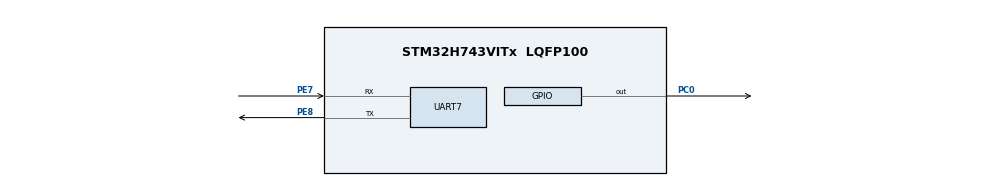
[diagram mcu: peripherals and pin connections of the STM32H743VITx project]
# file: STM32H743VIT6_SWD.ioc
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Mcu.Family=STM32H7
Mcu.Name=STM32H743VITx
Mcu.Package=LQFP100
NVIC.PriorityGroup=NVIC_PRIORITYGROUP_4
PA13\ (JTMS/SWDIO).Mode=JTAG_4_pins
PA13\ (JTMS/SWDIO).Signal=DEBUG_JTMS-SWDIO
PA14\ (JTCK/SWCLK).Mode=JTAG_4_pins
PA14\ (JTCK/SWCLK).Signal=DEBUG_JTCK-SWCLK
PA15\ (JTDI).Mode=JTAG_4_pins
PA15\ (JTDI).Signal=DEBUG_JTDI
PB3\ (JTDO/TRACESWO).Mode=JTAG_4_pins
PB3\ (JTDO/TRACESWO).Signal=DEBUG_JTDO-SWO
PC0.GPIO_ModeDefaultOutputPP=GPIO_MODE_OUTPUT_PP
PC0.GPIO_PuPd=GPIO_NOPULL
PC0.PinState=GPIO_PIN_SET
PC0.Signal=GPIO_Output
PE7.Mode=Asynchronous
PE7.Signal=UART7_RX
PE8.Mode=Asynchronous
PE8.Signal=UART7_TX
ProjectManager.HeapSize=0x200
ProjectManager.StackSize=0x400
ProjectManager.TargetToolchain=STM32CubeIDE
RCC.ADCFreq_Value=129000000
RCC.APB1Freq_Value=32000000
RCC.APB2Freq_Value=64000000
RCC.APB3Freq_Value=64000000
RCC.APB4Freq_Value=64000000
RCC.CortexFreq_Value=64000000
RCC.D2PPRE1=RCC_APB1_DIV2
RCC.HCLKFreq_Value=64000000
RCC.SYSCLKFreq_VALUE=64000000
RCC.USBFreq_Value=129000000
board=custom

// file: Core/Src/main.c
/* USER CODE BEGIN Header */
/**
  ******************************************************************************
  * @file           : main.c
  * @brief          : Main program body
  ******************************************************************************
  * @attention
  *
  * Copyright (c) 2022 STMicroelectronics.
  * All rights reserved.
  *
  * This software is licensed under terms that can be found in the LICENSE file
  * in the root directory of this software component.
  * If no LICENSE file comes with this software, it is provided AS-IS.
  *
  ******************************************************************************
  */
/* USER CODE END Header */
#include "main.h"

/* USER CODE BEGIN PM */
#define PRINT(...) printf(__VA_ARGS__)
/* USER CODE END PM */

UART_HandleTypeDef huart7;

void SystemClock_Config(void);
static void MX_GPIO_Init(void);
static void MX_UART7_Init(void);

/* USER CODE BEGIN 0 */
int __io_putchar(int ch)
{
	ITM_SendChar(ch);
	return(ch);
}
/* USER CODE END 0 */

int main(void)
{

  /* MCU Configuration--------------------------------------------------------*/

  /* Reset of all peripherals, Initializes the Flash interface and the Systick. */
  HAL_Init();

  /* Configure the system clock */
  SystemClock_Config();

  /* Initialize all configured peripherals */
  MX_GPIO_Init();
  MX_UART7_Init();
  /* USER CODE BEGIN 2 */
  PRINT("Led ON\n");
  HAL_Delay(1000);
  HAL_GPIO_TogglePin(GPIOC, GPIO_PIN_0);		// turn led (PC0) off
  PRINT("Led OFF\n");
  /* USER CODE END 2 */

  /* Infinite loop */
  while (1)
  {

  }
}

void SystemClock_Config(void)
{
  RCC_OscInitTypeDef RCC_OscInitStruct = {0};
  RCC_ClkInitTypeDef RCC_ClkInitStruct = {0};

  /** Supply configuration update enable
  */
  HAL_PWREx_ConfigSupply(PWR_LDO_SUPPLY);

  /** Configure the main internal regulator output voltage
  */
  __HAL_PWR_VOLTAGESCALING_CONFIG(PWR_REGULATOR_VOLTAGE_SCALE3);

  while(!__HAL_PWR_GET_FLAG(PWR_FLAG_VOSRDY)) {}

  /** Initializes the RCC Oscillators according to the specified parameters
  * in the RCC_OscInitTypeDef structure.
  */
  RCC_OscInitStruct.OscillatorType = RCC_OSCILLATORTYPE_HSI;
  RCC_OscInitStruct.HSIState = RCC_HSI_DIV1;
  RCC_OscInitStruct.HSICalibrationValue = RCC_HSICALIBRATION_DEFAULT;
  RCC_OscInitStruct.PLL.PLLState = RCC_PLL_NONE;
  if (HAL_RCC_OscConfig(&RCC_OscInitStruct) != HAL_OK)
  {
    Error_Handler();
  }

  /** Initializes the CPU, AHB and APB buses clocks
  */
  RCC_ClkInitStruct.ClockType = RCC_CLOCKTYPE_HCLK|RCC_CLOCKTYPE_SYSCLK
                              |RCC_CLOCKTYPE_PCLK1|RCC_CLOCKTYPE_PCLK2
                              |RCC_CLOCKTYPE_D3PCLK1|RCC_CLOCKTYPE_D1PCLK1;
  RCC_ClkInitStruct.SYSCLKSource = RCC_SYSCLKSOURCE_HSI;
  RCC_ClkInitStruct.SYSCLKDivider = RCC_SYSCLK_DIV1;
  RCC_ClkInitStruct.AHBCLKDivider = RCC_HCLK_DIV1;
  RCC_ClkInitStruct.APB3CLKDivider = RCC_APB3_DIV1;
  RCC_ClkInitStruct.APB1CLKDivider = RCC_APB1_DIV2;
  RCC_ClkInitStruct.APB2CLKDivider = RCC_APB2_DIV1;
  RCC_ClkInitStruct.APB4CLKDivider = RCC_APB4_DIV1;

  if (HAL_RCC_ClockConfig(&RCC_ClkInitStruct, FLASH_LATENCY_1) != HAL_OK)
  {
    Error_Handler();
  }
}

static void MX_UART7_Init(void)
{

  huart7.Instance = UART7;
  huart7.Init.BaudRate = 115200;
  huart7.Init.WordLength = UART_WORDLENGTH_8B;
  huart7.Init.StopBits = UART_STOPBITS_1;
  huart7.Init.Parity = UART_PARITY_NONE;
  huart7.Init.Mode = UART_MODE_TX_RX;
  huart7.Init.HwFlowCtl = UART_HWCONTROL_NONE;
  huart7.Init.OverSampling = UART_OVERSAMPLING_16;
  huart7.Init.OneBitSampling = UART_ONE_BIT_SAMPLE_DISABLE;
  huart7.Init.ClockPrescaler = UART_PRESCALER_DIV1;
  huart7.AdvancedInit.AdvFeatureInit = UART_ADVFEATURE_NO_INIT;
  if (HAL_UART_Init(&huart7) != HAL_OK)
  {
    Error_Handler();
  }
  if (HAL_UARTEx_SetTxFifoThreshold(&huart7, UART_TXFIFO_THRESHOLD_1_8) != HAL_OK)
  {
    Error_Handler();
  }
  if (HAL_UARTEx_SetRxFifoThreshold(&huart7, UART_RXFIFO_THRESHOLD_1_8) != HAL_OK)
  {
    Error_Handler();
  }
  if (HAL_UARTEx_DisableFifoMode(&huart7) != HAL_OK)
  {
    Error_Handler();
  }

}

static void MX_GPIO_Init(void)
{
  GPIO_InitTypeDef GPIO_InitStruct = {0};

  /* GPIO Ports Clock Enable */
  __HAL_RCC_GPIOC_CLK_ENABLE();
  __HAL_RCC_GPIOE_CLK_ENABLE();
  __HAL_RCC_GPIOA_CLK_ENABLE();
  __HAL_RCC_GPIOB_CLK_ENABLE();

  /*Configure GPIO pin Output Level */
  HAL_GPIO_WritePin(GPIOC, GPIO_PIN_0, GPIO_PIN_SET);

  /*Configure GPIO pin : PC0 */
  GPIO_InitStruct.Pin = GPIO_PIN_0;
  GPIO_InitStruct.Mode = GPIO_MODE_OUTPUT_PP;
  GPIO_InitStruct.Pull = GPIO_NOPULL;
  GPIO_InitStruct.Speed = GPIO_SPEED_FREQ_LOW;
  HAL_GPIO_Init(GPIOC, &GPIO_InitStruct);

}

void Error_Handler(void)
{
  __disable_irq();
  while (1)
  {
  }
}
